VERSION ""

NS_ :

BS_:

BU_: _4WD AFLS AHLS AVM CLU CUBIS ECS EMS EPB IBOX LDWS_LKAS PGS PSB SCC SMK SPAS TCU TPMS ACU LCA BCM LPI TMU MDPS ESC ODS DATC ABS AEMC EVP FPCM CGW FATC IAP AAF DI_BOX REA SAS LVR XXX

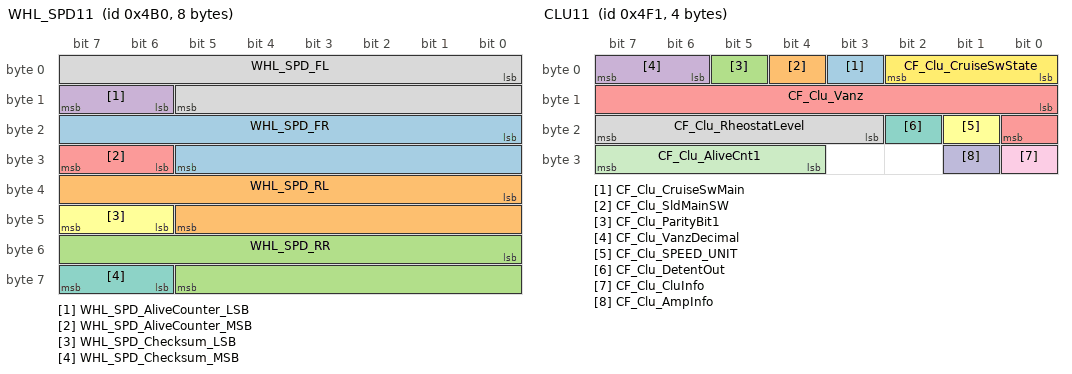
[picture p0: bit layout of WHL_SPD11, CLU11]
BO_ 1200 WHL_SPD11: 8 ABS
 SG_ WHL_SPD_FR : 16|14@1+ (0.03125,0) [0|511.96875] "km/h" _4WD,ACU,AFLS,AHLS,AVM,CLU,CUBIS,ECS,EMS,EPB,IBOX,LDWS_LKAS,PGS,PSB,SCC,SMK,SPAS,TCU,TPMS,_4WD,ACU,AFLS,AHLS,AVM,CLU,ECS,EMS,EPB,IBOX,LCA,LDWS_LKAS,PGS,PSB,SCC,SMK,SPAS,TCU,TPMS
 SG_ WHL_SPD_RL : 32|14@1+ (0.03125,0) [0|511.96875] "km/h" _4WD,AFLS,AHLS,AVM,BCM,CLU,CUBIS,ECS,EMS,EPB,IBOX,LDWS_LKAS,PGS,PSB,SCC,SMK,SPAS,TCU,TPMS,_4WD,ACU,AFLS,AHLS,AVM,BCM,CLU,ECS,EMS,EPB,IBOX,LCA,LDWS_LKAS,PGS,PSB,SCC,SMK,SPAS,TCU,TPMS
 SG_ WHL_SPD_RR : 48|14@1+ (0.03125,0) [0|511.96875] "km/h" _4WD,AFLS,AHLS,AVM,CLU,CUBIS,ECS,EMS,EPB,IBOX,LDWS_LKAS,PGS,PSB,SCC,SMK,SPAS,TCU,TPMS,_4WD,ACU,AFLS,AHLS,AVM,CLU,ECS,EMS,EPB,IBOX,LCA,LDWS_LKAS,PGS,PSB,SCC,SMK,SPAS,TCU,TPMS
 SG_ WHL_SPD_AliveCounter_LSB : 14|2@1+ (1,0) [0|15] "" _4WD,EMS,LPI,TCU,TMU
 SG_ WHL_SPD_AliveCounter_MSB : 30|2@1+ (1,0) [0|15] "" _4WD,EMS,LPI,TCU,TMU
 SG_ WHL_SPD_Checksum_LSB : 46|2@1+ (1,0) [0|15] "" _4WD,EMS,LPI,TCU,TMU
 SG_ WHL_SPD_Checksum_MSB : 62|2@1+ (1,0) [0|15] "" _4WD,EMS,LPI,TCU,TMU
 SG_ WHL_SPD_FL : 0|14@1+ (0.03125,0) [0|511.96875] "km/h" _4WD,AFLS,AHLS,AVM,CLU,CUBIS,ECS,EMS,EPB,IBOX,LDWS_LKAS,PGS,PSB,SCC,SMK,SPAS,TCU,TPMS,_4WD,ACU,AFLS,AHLS,AVM,CLU,ECS,EMS,EPB,IBOX,LCA,LDWS_LKAS,PGS,PSB,SCC,SMK,SPAS,TCU,TPMS

BO_ 1265 CLU11: 4 CLU
 SG_ CF_Clu_CruiseSwMain : 3|1@1+ (1,0) [0|1] "" EMS,LDWS_LKAS,SCC
 SG_ CF_Clu_SldMainSW : 4|1@1+ (1,0) [0|1] "" EMS
 SG_ CF_Clu_ParityBit1 : 5|1@1+ (1,0) [0|1] "pulse count" EMS
 SG_ CF_Clu_VanzDecimal : 6|2@1+ (0.125,0) [0|0.375] "" EMS
 SG_ CF_Clu_Vanz : 8|9@1+ (0.5,0) [0|255.5] "km/h or MPH" BCM,CUBIS,EMS,IBOX,LDWS_LKAS,MDPS,SCC
 SG_ CF_Clu_SPEED_UNIT : 17|1@1+ (1,0) [0|1] "" BCM,CUBIS,EMS,IBOX,LDWS_LKAS,MDPS,SCC
 SG_ CF_Clu_DetentOut : 18|1@1+ (1,0) [0|1] "" AVM,BCM,LCA,PGS,SPAS
 SG_ CF_Clu_RheostatLevel : 19|5@1+ (1,0) [0|31] "" AVM,BCM,LCA,PGS,SPAS
 SG_ CF_Clu_CluInfo : 24|1@1+ (1,0) [0|1] "" BCM
 SG_ CF_Clu_AmpInfo : 25|1@1+ (1,0) [0|1] "" BCM
 SG_ CF_Clu_AliveCnt1 : 28|4@1+ (1,0) [0|15] "" AHLS,EMS,EPB,LDWS_LKAS,MDPS,SCC
 SG_ CF_Clu_CruiseSwState : 0|3@1+ (1,0) [0|7] "" EMS,LDWS_LKAS,SCC

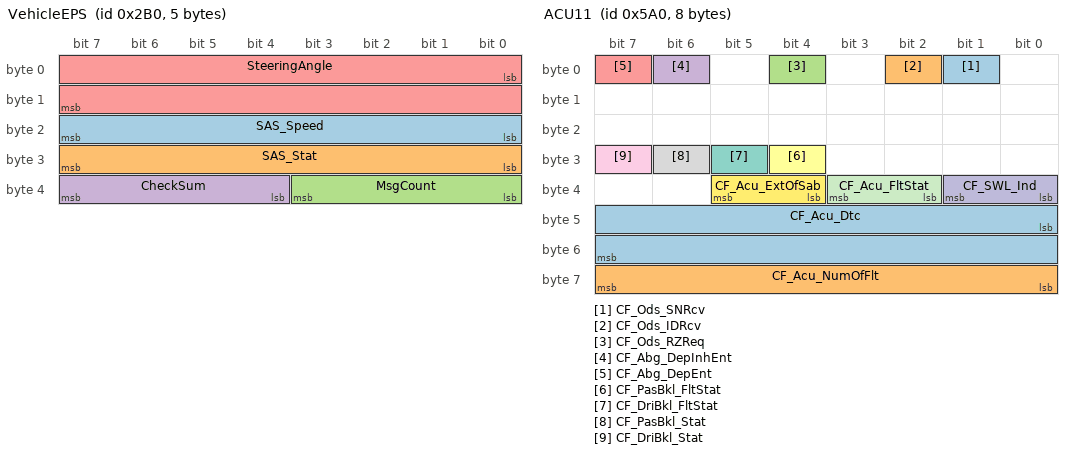
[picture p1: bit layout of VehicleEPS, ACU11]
BO_ 688 VehicleEPS: 5 MDPS
 SG_ SAS_Speed : 16|8@1+ (4,0) [0|1016] "" AFLS,ECS,ESC,IBOX,LDWS_LKAS,SCC,SPAS,TCU,AFLS,ECS,ESC,IBOX,LDWS_LKAS,SCC,SPAS,TCU
 SG_ SAS_Stat : 24|8@1+ (1,0) [0|255] "" ECS,ESC,IBOX,LDWS_LKAS,PSB,SCC,SPAS,TCU,ECS,ESC,IBOX,LDWS_LKAS,PSB,SCC,SPAS,TCU
 SG_ MsgCount : 32|4@1+ (1,0) [0|15] "" ECS,ESC,IBOX,LDWS_LKAS,PSB,SCC,SPAS,ECS,ESC,IBOX,LDWS_LKAS,PSB,SCC,SPAS
 SG_ CheckSum : 36|4@1+ (1,0) [0|15] "" ECS,EMS,ESC,IBOX,LDWS_LKAS,PSB,SCC,SPAS,ECS,EMS,ESC,IBOX,LDWS_LKAS,PSB,SCC,SPAS
 SG_ SteeringAngle : 0|16@1- (0.1,0) [-3276.8|3276.7] "Deg" _4WD,ACU,AFLS,AVM,CLU,ECS,EMS,ESC,IBOX,LCA,LDWS_LKAS,PGS,PSB,SCC,SPAS,TCU,_4WD,ACU,AFLS,AVM,BCM,CLU,ECS,EMS,ESC,IBOX,LCA,LDWS_LKAS,PGS,PSB,SCC,SPAS,TCU

BO_ 1440 ACU11: 8 ACU
 SG_ CF_Ods_SNRcv : 1|1@1+ (1,0) [0|1] "" ODS
 SG_ CF_Ods_IDRcv : 2|1@1+ (1,0) [0|1] "" ODS
 SG_ CF_Ods_RZReq : 4|1@1+ (1,0) [0|1] "" ODS
 SG_ CF_Abg_DepInhEnt : 6|1@1+ (1,0) [0|1] "" ODS
 SG_ CF_Abg_DepEnt : 7|1@1+ (1,0) [0|1] "" ODS
 SG_ CF_PasBkl_FltStat : 28|1@1+ (1,0) [0|1] "" ODS,PSB
 SG_ CF_DriBkl_FltStat : 29|1@1+ (1,0) [0|1] "" ODS,PSB
 SG_ CF_PasBkl_Stat : 30|1@1+ (1,0) [0|1] "" IBOX,ODS,PSB,TMU
 SG_ CF_DriBkl_Stat : 31|1@1+ (1,0) [0|1] "" ODS,PSB
 SG_ CF_SWL_Ind : 32|2@1+ (1,0) [0|3] "" CUBIS,IBOX
 SG_ CF_Acu_FltStat : 34|2@1+ (1,0) [0|3] "" CUBIS,IBOX
 SG_ CF_Acu_ExtOfSab : 36|2@1+ (1,0) [0|3] "" BCM,CLU,CUBIS,IBOX
 SG_ CF_Acu_Dtc : 40|16@1+ (1,0) [0|65535] "" CUBIS,IBOX
 SG_ CF_Acu_NumOfFlt : 56|8@1+ (1,0) [0|255] "" CUBIS,IBOX

BO_ 399 EMS_H12: 8 EMS
 SG_ R_TqAcnApvC : 0|8@1+ (0.2,0) [0|51] "Nm" DATC,IBOX
 SG_ R_PAcnC : 8|8@1+ (125,0) [0|31875] "hPa" DATC,IBOX
 SG_ TQI_B : 16|8@1+ (0.390625,0) [0|99.609375] "%" ABS,ESC,IBOX
 SG_ SLD_VS : 24|8@1+ (1,0) [0|255] "km/h" CLU,IBOX
 SG_ CF_CdaStat : 32|3@1+ (1,0) [0|7] "" AEMC,IBOX,TCU
 SG_ CF_Ems_IsgStat : 35|3@1+ (1,0) [0|7] "" ABS,BCM,CLU,DATC,EPB,ESC,IBOX,LDWS_LKAS,MDPS,SMK,TCU
 SG_ CF_Ems_OilChg : 38|1@1+ (1,0) [0|1] "" CLU,IBOX
 SG_ CF_Ems_EtcLimpMod : 39|1@1+ (1,0) [0|1] "" CLU,IBOX
 SG_ R_NEngIdlTgC : 40|8@1+ (10,0) [0|2550] "rpm" DATC,IBOX,TCU
 SG_ CF_Ems_UpTarGr : 48|1@1+ (1,0) [0|1] "" CLU,IBOX
 SG_ CF_Ems_DownTarGr : 49|1@1+ (1,0) [0|1] "" CLU,IBOX
 SG_ CF_Ems_DesCurGr : 50|4@1+ (1,0) [0|15] "" CLU,IBOX
 SG_ CF_Ems_SldAct : 54|1@1+ (1,0) [0|1] "" CLU,IBOX
 SG_ CF_Ems_SldPosAct : 55|1@1+ (1,0) [0|1] "" CLU,IBOX
 SG_ CF_Ems_HPresStat : 56|1@1+ (1,0) [0|1] "" IBOX,TCU
 SG_ CF_Ems_IsgBuz : 57|1@1+ (1,0) [0|1] "" CLU,IBOX
 SG_ CF_Ems_IdlStpFCO : 58|1@1+ (1,0) [0|1] "" CLU,IBOX
 SG_ CF_Ems_FCopen : 59|1@1+ (1,0) [0|1] "" CLU,IBOX
 SG_ CF_Ems_ActEcoAct : 60|1@1+ (1,0) [0|1] "" CLU,IBOX,TCU
 SG_ CF_Ems_EngRunNorm : 61|1@1+ (1,0) [0|1] "" ABS,ESC,IBOX,TCU
 SG_ CF_Ems_IsgStat2 : 62|2@1+ (2,0) [0|3] "" CLU,IBOX,TCU

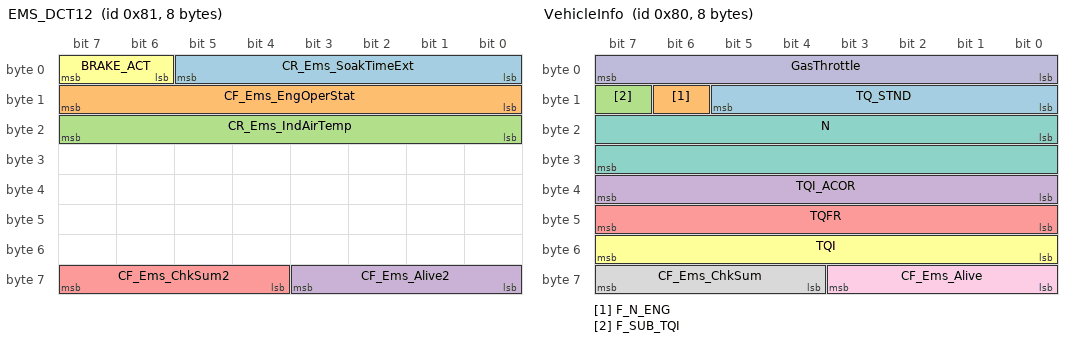
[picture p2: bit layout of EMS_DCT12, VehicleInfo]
BO_ 129 EMS_DCT12: 8 EMS
 SG_ CR_Ems_SoakTimeExt : 0|6@1+ (5,0) [0|315] "Min" TCU
 SG_ CF_Ems_EngOperStat : 8|8@1+ (1,0) [0|255] "" TCU
 SG_ CR_Ems_IndAirTemp : 16|8@1+ (0.75,-48) [-48|143.25] "deg" TCU
 SG_ CF_Ems_Alive2 : 56|4@1+ (1,0) [0|15] "" TCU
 SG_ CF_Ems_ChkSum2 : 60|4@1+ (1,0) [0|15] "" TCU
 SG_ BRAKE_ACT : 6|2@1+ (1,0) [0|3] "" TCU

BO_ 128 VehicleInfo: 8 EMS
 SG_ TQ_STND : 8|6@1+ (10,0) [0|630] "Nm" TCU
 SG_ F_N_ENG : 14|1@1+ (1,0) [0|1] "" TCU
 SG_ F_SUB_TQI : 15|1@1+ (1,0) [0|1] "" TCU
 SG_ TQI_ACOR : 32|8@1+ (0.390625,0) [0|99.6094] "%" IBOX,TCU
 SG_ TQFR : 40|8@1+ (0.390625,0) [0|99.6094] "%" TCU
 SG_ TQI : 48|8@1+ (0.390625,0) [0|99.609375] "%" TCU
 SG_ N : 16|16@1+ (0.25,0) [0|16383.75] "rpm" TCU
 SG_ CF_Ems_ChkSum : 60|4@1+ (1,0) [0|15] "" TCU
 SG_ CF_Ems_Alive : 56|4@1+ (1,0) [0|15] "" TCU
 SG_ GasThrottle : 0|8@1+ (0.3906,0) [0|99.603] "%" TCU

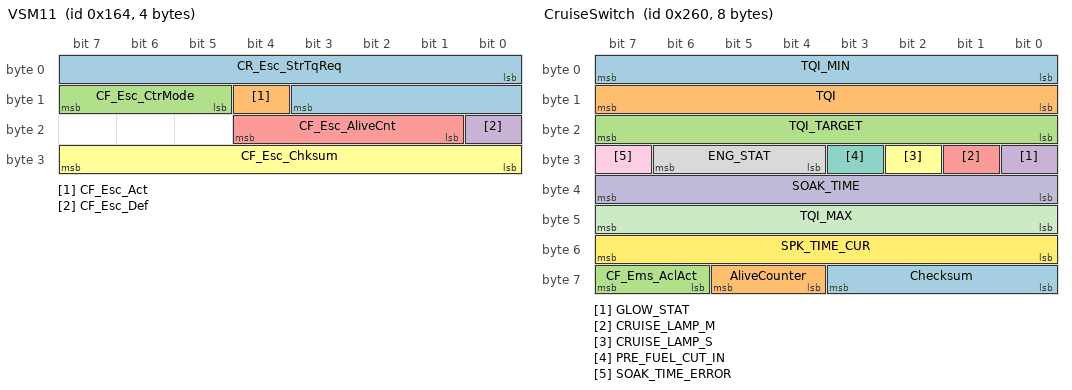
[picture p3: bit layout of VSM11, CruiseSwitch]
BO_ 356 VSM11: 4 ESC
 SG_ CR_Esc_StrTqReq : 0|12@1+ (0.01,-20.48) [-20.48|20.47] "Nm" MDPS
 SG_ CF_Esc_Act : 12|1@1+ (1,0) [0|1] "" LDWS_LKAS,MDPS
 SG_ CF_Esc_CtrMode : 13|3@1+ (1,0) [0|7] "" MDPS
 SG_ CF_Esc_Def : 16|1@1+ (1,0) [0|1] "" MDPS
 SG_ CF_Esc_AliveCnt : 17|4@1+ (1,0) [0|15] "" LDWS_LKAS,MDPS
 SG_ CF_Esc_Chksum : 24|8@1+ (1,0) [0|255] "" LDWS_LKAS,MDPS

BO_ 608 CruiseSwitch: 8 EMS
 SG_ TQI_MIN : 0|8@1+ (0.390625,0) [0|99.609375] "%" ESC,IBOX,TCU
 SG_ TQI : 8|8@1+ (0.390625,0) [0|99.609375] "%" ESC,IBOX,TCU
 SG_ TQI_TARGET : 16|8@1+ (0.390625,0) [0|99.609375] "%" EPB,ESC,IBOX,TCU
 SG_ GLOW_STAT : 24|1@1+ (1,0) [0|1] "" BCM,CLU,IBOX,SMK
 SG_ CRUISE_LAMP_M : 25|1@1+ (1,0) [0|1] "" CLU,IBOX,TCU
 SG_ CRUISE_LAMP_S : 26|1@1+ (1,0) [0|1] "" CLU,IBOX,TCU
 SG_ PRE_FUEL_CUT_IN : 27|1@1+ (1,0) [0|1] "" IBOX,TCU
 SG_ ENG_STAT : 28|3@1+ (1,0) [0|7] "" ABS,AHLS,AVM,BCM,CLU,EPB,ESC,EVP,FPCM,IBOX,LCA,LDWS_LKAS,MDPS,SCC,SMK,TCU
 SG_ SOAK_TIME_ERROR : 31|1@1+ (1,0) [0|1] "" DATC,EPB,IBOX,TCU
 SG_ SOAK_TIME : 32|8@1+ (1,0) [0|255] "Min" _4WD,DATC,EPB,IBOX,TCU
 SG_ TQI_MAX : 40|8@1+ (0.390625,0) [0|99.609375] "%" ESC,IBOX,TCU
 SG_ SPK_TIME_CUR : 48|8@1+ (0.375,-35.625) [-35.625|60] "" IBOX,TCU
 SG_ Checksum : 56|4@1+ (1,0) [0|15] "" ECS,IBOX,LDWS_LKAS,MDPS,SCC
 SG_ AliveCounter : 60|2@1+ (1,0) [0|3] "" IBOX,LDWS_LKAS,MDPS,SCC
 SG_ CF_Ems_AclAct : 62|2@1+ (1,0) [0|3] "" IBOX,SCC

BO_ 339 TCS11: 8 ESC
 SG_ TCS_REQ : 0|1@1+ (1,0) [0|1] "" _4WD,EMS,EPB,TCU
 SG_ MSR_C_REQ : 1|1@1+ (1,0) [0|1] "" EMS,EPB,SCC,TCU
 SG_ TCS_PAS : 2|1@1+ (1,0) [0|1] "" _4WD,CLU,EMS,SCC,SPAS,TCU
 SG_ TCS_GSC : 3|1@1+ (1,0) [0|1] "" _4WD,EMS,TCU
 SG_ CF_Esc_LimoInfo : 4|2@1+ (1,0) [0|3] "" _4WD,SCC
 SG_ ABS_DIAG : 6|1@1+ (1,0) [0|1] "" _4WD,CLU,EMS,EPB
 SG_ ABS_DEF : 7|1@1+ (1,0) [0|1] "" _4WD,ACU,ECS,EMS,EPB,SCC,SPAS,TCU
 SG_ TCS_DEF : 8|1@1+ (1,0) [0|1] "" _4WD,EMS,EPB,SCC,SPAS,TCU
 SG_ TCS_CTL : 9|1@1+ (1,0) [0|1] "" _4WD,EMS,EPB,SCC,SPAS,TCU
 SG_ EBD_DEF : 11|1@1+ (1,0) [0|1] "" _4WD,EMS,EPB,SPAS,TCU
 SG_ ESP_PAS : 12|1@1+ (1,0) [0|1] "" _4WD,ACU,CLU,EMS,EPB,LDWS_LKAS,SCC,TCU
 SG_ ESP_DEF : 13|1@1+ (1,0) [0|1] "" _4WD,ACU,ECS,EMS,EPB,LDWS_LKAS,SCC,TCU
 SG_ ESP_CTL : 14|1@1+ (1,0) [0|1] "" _4WD,ACU,ECS,EMS,EPB,LDWS_LKAS,SCC,SPAS,TCU
 SG_ TCS_MFRN : 15|1@1+ (1,0) [0|1] "" EMS,EPB,TCU
 SG_ DBC_CTL : 16|1@1+ (1,0) [0|1] "" _4WD,EMS,EPB
 SG_ DBC_PAS : 17|1@1+ (1,0) [0|1] "" _4WD,EMS,EPB
 SG_ DBC_DEF : 18|1@1+ (1,0) [0|1] "" _4WD,EMS,EPB
 SG_ HAC_CTL : 19|1@1+ (1,0) [0|1] "" _4WD,CLU,EMS,EPB,TCU
 SG_ HAC_PAS : 20|1@1+ (1,0) [0|1] "" _4WD,CLU,EMS,EPB,TCU
 SG_ HAC_DEF : 21|1@1+ (1,0) [0|1] "" _4WD,CLU,EMS,EPB,TCU
 SG_ ESS_STAT : 22|2@1+ (1,0) [0|3] "" _4WD,BCM,CLU,EMS,EPB
 SG_ TQI_TCS : 24|8@1+ (0.390625,0) [0|99.609375] "%" EMS,EPB,TCU
 SG_ TQI_MSR : 32|8@1+ (0.390625,0) [0|99.609375] "%" EMS,EPB,TCU
 SG_ TQI_SLW_TCS : 40|8@1+ (0.390625,0) [0|99.609375] "%" EMS,EPB,TCU
 SG_ CF_Esc_BrkCtl : 48|1@1+ (1,0) [0|1] "" EMS
 SG_ BLA_CTL : 49|2@1+ (1,0) [0|3] "" BCM,CGW,CLU
 SG_ AliveCounter_TCS1 : 52|4@1+ (1,0) [0|14] "" EMS,EPB,LDWS_LKAS
 SG_ CheckSum_TCS1 : 56|8@1+ (1,0) [0|255] "" EMS,EPB,LDWS_LKAS
 SG_ ABS_ACT : 10|1@1+ (1,0) [0|1] "" _4WD,ACU,ECS,EMS,EPB,LDWS_LKAS,SCC,SPAS,TCU

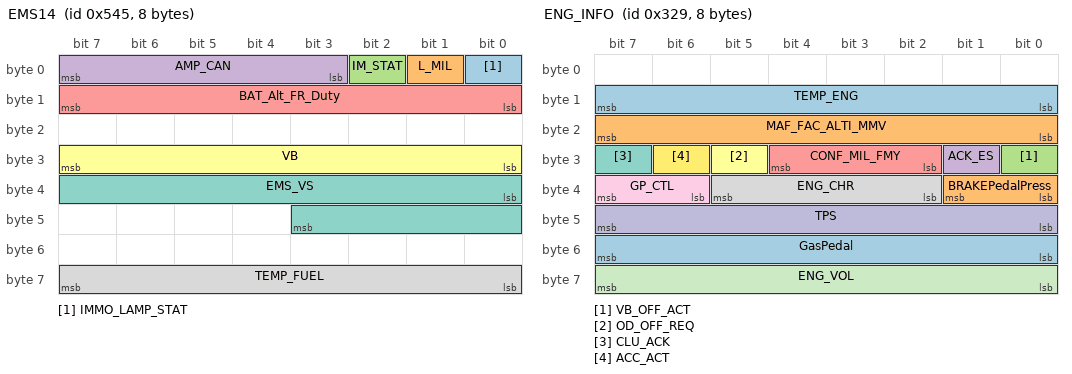
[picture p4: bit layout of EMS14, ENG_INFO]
BO_ 1349 EMS14: 8 EMS
 SG_ IMMO_LAMP_STAT : 0|1@1+ (1,0) [0|1] "" CLU,IBOX
 SG_ L_MIL : 1|1@1+ (1,0) [0|1] "" CLU,CUBIS,IBOX
 SG_ IM_STAT : 2|1@1+ (1,0) [0|1] "" CLU,IBOX
 SG_ AMP_CAN : 3|5@1+ (10.731613,458.98) [458.98|791.660003] "mmHg" CLU,IBOX,TCU,TPMS
 SG_ BAT_Alt_FR_Duty : 8|8@1+ (0.4,0) [0|100] "%" CGW,CUBIS,IBOX,TMU
 SG_ VB : 24|8@1+ (0.1015625,0) [0|25.8984375] "V" CLU,CUBIS,DATC,EPB,FPCM,IBOX
 SG_ EMS_VS : 32|12@1+ (0.0625,0) [0|255.875] "km/h" CLU
 SG_ TEMP_FUEL : 56|8@1+ (0.75,-48) [-48|143.25] "deg" FPCM

BO_ 809 ENG_INFO: 8 EMS
 SG_ TEMP_ENG : 8|8@1+ (0.75,-48) [-48|143.25] "deg" _4WD,BCM,CLU,DATC,EPB,ESC,IBOX,SMK,TCU
 SG_ MAF_FAC_ALTI_MMV : 16|8@1+ (0.00781,0) [0|1.99155] "" IBOX,TCU
 SG_ VB_OFF_ACT : 24|1@1+ (1,0) [0|1] "" IBOX,TCU
 SG_ ACK_ES : 25|1@1+ (1,0) [0|1] "" _4WD,ACU,IBOX
 SG_ CONF_MIL_FMY : 26|3@1+ (1,0) [0|7] "" ESC,IBOX,TCU
 SG_ OD_OFF_REQ : 29|1@1+ (1,0) [0|1] "" IBOX,TCU
 SG_ CLU_ACK : 31|1@1+ (1,0) [0|1] "" _4WD,EPB,ESC,IBOX
 SG_ ENG_CHR : 34|4@1+ (1,0) [0|15] "" _4WD,ABS,ACU,CLU,DATC,EPB,ESC,FATC,IBOX,SCC,SMK,TCU
 SG_ GP_CTL : 38|2@1+ (1,0) [0|3] "" IBOX
 SG_ TPS : 40|8@1+ (0.4694836,-15.0234742) [-15.0234742|104.6948357] "%" _4WD,ABS,ACU,CLU,DATC,ECS,EPB,ESC,IBOX,TCU
 SG_ ENG_VOL : 56|8@1+ (0.1,0) [0|25.5] "liter" _4WD,ABS,ACU,BCM,CLU,DATC,EPB,ESC,IBOX,LDWS_LKAS,SCC,SMK
 SG_ ACC_ACT : 30|1@1+ (1,0) [0|1] "" _4WD,ABS,CLU,ESC,IAP,IBOX,SCC,TCU
 SG_ GasPedal : 48|8@1+ (0.3906,0) [0|99.603] "%" _4WD,AAF,ABS,ACU,AFLS,CLU,DATC,EPB,ESC,IAP,IBOX,LDWS_LKAS,SCC,TCU
 SG_ BRAKEPedalPress : 32|2@1+ (1,0) [0|3] "" _4WD,ABS,ACU,AFLS,CLU,DATC,ECS,EPB,ESC,IBOX,LDWS_LKAS,TCU

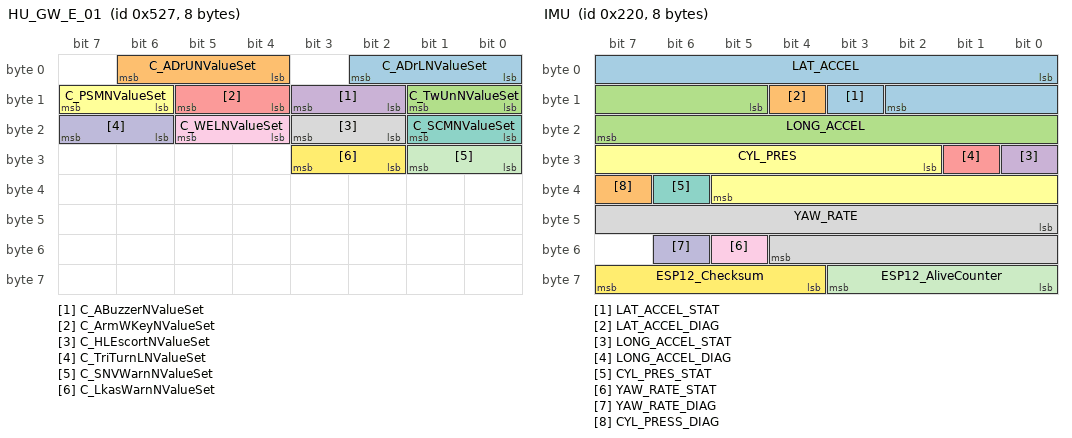
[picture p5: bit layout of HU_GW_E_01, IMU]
BO_ 1319 HU_GW_E_01: 8 CLU
 SG_ C_ADrLNValueSet : 0|3@1+ (1,0) [0|7] "" BCM
 SG_ C_ADrUNValueSet : 4|3@1+ (1,0) [0|7] "" BCM
 SG_ C_TwUnNValueSet : 8|2@1+ (1,0) [0|3] "" BCM
 SG_ C_ABuzzerNValueSet : 10|2@1+ (1,0) [0|3] "" BCM
 SG_ C_ArmWKeyNValueSet : 12|2@1+ (1,0) [0|3] "" BCM
 SG_ C_PSMNValueSet : 14|2@1+ (1,0) [0|3] "" BCM
 SG_ C_SCMNValueSet : 16|2@1+ (1,0) [0|3] "" BCM
 SG_ C_HLEscortNValueSet : 18|2@1+ (1,0) [0|3] "" BCM
 SG_ C_WELNValueSet : 20|2@1+ (1,0) [0|3] "" BCM
 SG_ C_TriTurnLNValueSet : 22|2@1+ (1,0) [0|3] "" BCM
 SG_ C_SNVWarnNValueSet : 24|2@1+ (1,0) [0|3] "" BCM
 SG_ C_LkasWarnNValueSet : 26|2@1+ (1,0) [0|3] "" BCM

BO_ 544 IMU: 8 ESC
 SG_ LAT_ACCEL_STAT : 11|1@1+ (1,0) [0|1] "" _4WD,IBOX,LDWS_LKAS,MDPS,PSB,SCC,TCU
 SG_ LAT_ACCEL_DIAG : 12|1@1+ (1,0) [0|1] "" _4WD,IBOX,LDWS_LKAS,MDPS,PSB,SCC,TCU
 SG_ LONG_ACCEL : 13|11@1+ (0.01,-10.23) [-10.23|10.24] "m/s^2" _4WD,ECS,EMS,EPB,IBOX,LCA,LDWS_LKAS,PSB,SCC,SPAS,TCU
 SG_ LONG_ACCEL_STAT : 24|1@1+ (1,0) [0|1] "" _4WD,EMS,EPB,IBOX,LDWS_LKAS,PSB,SCC,SPAS,TCU
 SG_ LONG_ACCEL_DIAG : 25|1@1+ (1,0) [0|1] "" _4WD,EMS,EPB,IBOX,LDWS_LKAS,PSB,SCC,SPAS,TCU
 SG_ CYL_PRES : 26|12@1+ (0.1,0) [0|409.5] "Bar" _4WD,ECS,EMS,EPB,IBOX,LDWS_LKAS,PSB,SCC,TCU
 SG_ CYL_PRES_STAT : 38|1@1+ (1,0) [0|1] "" _4WD,ECS,EMS,EPB,IBOX,LDWS_LKAS,PSB,SCC,TCU
 SG_ YAW_RATE : 40|13@1+ (0.01,-40.95) [-40.95|40.96] "" _4WD,AFLS,IBOX,LCA,LDWS_LKAS,MDPS,PSB,SCC,SPAS,TCU
 SG_ YAW_RATE_STAT : 53|1@1+ (1,0) [0|1] "" _4WD,AFLS,IBOX,LCA,LDWS_LKAS,MDPS,PSB,SCC,SPAS,TCU
 SG_ YAW_RATE_DIAG : 54|1@1+ (1,0) [0|1] "" _4WD,AFLS,IBOX,LCA,LDWS_LKAS,MDPS,PSB,SCC,SPAS,TCU
 SG_ ESP12_AliveCounter : 56|4@1+ (1,0) [0|15] "" _4WD,EMS,LPI,TCU,TMU
 SG_ ESP12_Checksum : 60|4@1+ (1,0) [0|15] "" _4WD,EMS,LPI,TCU,TMU
 SG_ LAT_ACCEL : 0|11@1+ (0.01,-10.23) [-10.23|10.24] "m/s^2" _4WD,ECS,IBOX,LCA,LDWS_LKAS,MDPS,PSB,SCC,TCU
 SG_ CYL_PRESS_DIAG : 39|1@1+ (1,0) [0|1] "" _4WD,ECS,EMS,EPB,IBOX,PSB,SCC,TCU

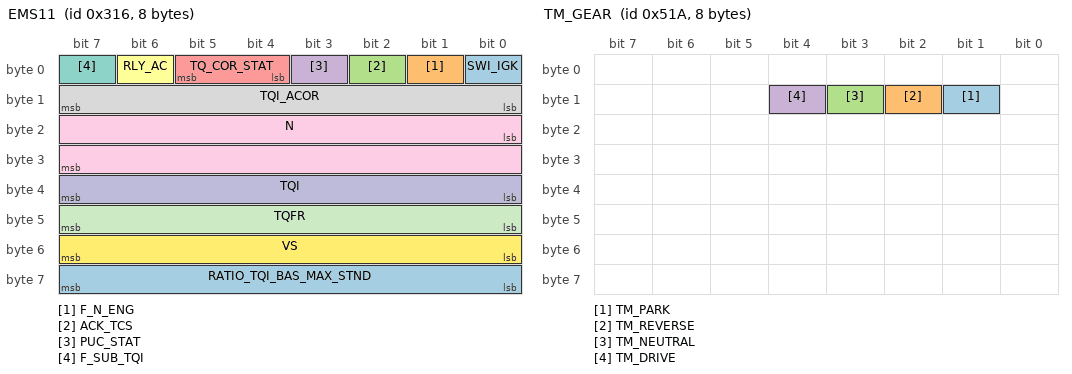
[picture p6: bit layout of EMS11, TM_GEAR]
BO_ 790 EMS11: 8 EMS
 SG_ SWI_IGK : 0|1@1+ (1,0) [0|1] "" _4WD,ABS,ACU,AHLS,CUBIS,DI_BOX,ECS,EPB,ESC,IBOX,LDWS_LKAS,MDPS,REA,SAS,SCC,TCU
 SG_ F_N_ENG : 1|1@1+ (1,0) [0|1] "" _4WD,ACU,AFLS,CLU,CUBIS,DATC,ECS,EPB,ESC,IBOX,MDPS,SCC,TCU
 SG_ ACK_TCS : 2|1@1+ (1,0) [0|1] "" ESC,IBOX
 SG_ PUC_STAT : 3|1@1+ (1,0) [0|1] "" _4WD,CLU,DATC,IBOX,TCU
 SG_ TQ_COR_STAT : 4|2@1+ (1,0) [0|3] "" _4WD,ESC,IBOX,TCU
 SG_ RLY_AC : 6|1@1+ (1,0) [0|1] "" DATC,IBOX,TCU
 SG_ F_SUB_TQI : 7|1@1+ (1,0) [0|1] "" _4WD,ECS,EPB,ESC,IBOX,TCU
 SG_ TQI_ACOR : 8|8@1+ (0.390625,0) [0|99.6094] "%" _4WD,EPB,ESC,IBOX,TCU
 SG_ N : 16|16@1+ (0.25,0) [0|16383.75] "rpm" _4WD,ACU,AFLS,CLU,CUBIS,DATC,ECS,EPB,ESC,FPCM,IBOX,MDPS,SCC,TCU
 SG_ TQI : 32|8@1+ (0.390625,0) [0|99.6094] "%" _4WD,ECS,EPB,ESC,IBOX,TCU
 SG_ TQFR : 40|8@1+ (0.390625,0) [0|99.6094] "%" _4WD,EPB,ESC,IBOX,TCU
 SG_ VS : 48|8@1+ (1,0) [0|254] "km/h" _4WD,AAF,ACU,AHLS,BCM,CLU,DATC,ECS,EPB,IBOX,LCA,LDWS_LKAS,LVR,MDPS,ODS,SCC,SMK,SPAS,TCU,TPMS
 SG_ RATIO_TQI_BAS_MAX_STND : 56|8@1+ (0.0078,0) [0|2] "" _4WD,IBOX,TCU

BO_ 1306 TM_GEAR: 8 XXX
 SG_ TM_PARK : 9|1@0+ (1,0) [0|1] "" XXX
 SG_ TM_REVERSE : 10|1@0+ (1,0) [0|1] "" XXX
 SG_ TM_NEUTRAL : 11|1@0+ (1,0) [0|1] "" XXX
 SG_ TM_DRIVE : 12|1@0+ (1,0) [0|1] "" XXX

BO_ 1508 Steering_DRIVE_MODE: 8 XXX
 SG_ DRIVE_MODE : 9|2@0+ (1,0) [0|2] "" XXX
 SG_ DriveModeInfo : 11|1@0+ (1,0) [0|1] "" XXX

CM_ SG_ 1508 DRIVE_MODE "Drive Mode: 0: Normal, 1 :Sport , 2: Comfort";
